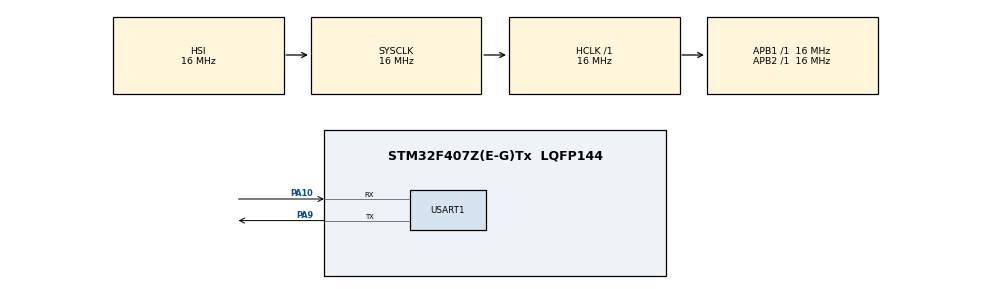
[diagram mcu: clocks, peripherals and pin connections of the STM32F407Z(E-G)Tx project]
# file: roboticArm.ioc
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Mcu.Family=STM32F4
Mcu.Name=STM32F407Z(E-G)Tx
Mcu.Package=LQFP144
NVIC.PriorityGroup=NVIC_PRIORITYGROUP_4
PA10.Mode=Asynchronous
PA10.Signal=USART1_RX
PA13.Mode=Serial_Wire
PA13.Signal=SYS_JTMS-SWDIO
PA14.Mode=Serial_Wire
PA14.Signal=SYS_JTCK-SWCLK
PA9.Mode=Asynchronous
PA9.Signal=USART1_TX
ProjectManager.HeapSize=0x200
ProjectManager.StackSize=0x400
ProjectManager.TargetToolchain=CMake
RCC.AHBFreq_Value=16000000
RCC.APB1Freq_Value=16000000
RCC.APB2Freq_Value=16000000
RCC.CortexFreq_Value=16000000
RCC.HSE_VALUE=25000000
RCC.HSI_VALUE=16000000
RCC.LSE_VALUE=32768
RCC.SYSCLKFreq_VALUE=16000000
RCC.VCOOutputFreq_Value=192000000
USART1.VirtualMode=VM_ASYNC
board=custom

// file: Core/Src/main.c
#include "main.h"
UART_HandleTypeDef huart1;

/* USER CODE BEGIN PV */
static const uint16_t servo_pulse_us[] = {1500U, 1300U, 1500U, 1700U};
static volatile uint32_t stepper_completed_moves = 0U;
/* USER CODE END PV */

void SystemClock_Config(void);
static void MX_GPIO_Init(void);
static void MX_USART1_UART_Init(void);

/* USER CODE BEGIN 0 */
/* D36A: STEP and DIR on GPIOC; active-high enables on GPIOD. */
#define STEP_A GPIO_PIN_6
#define DIR_A  GPIO_PIN_7
#define STEP_B GPIO_PIN_8
#define DIR_B  GPIO_PIN_9
#define EN_A   GPIO_PIN_6
#define EN_B   GPIO_PIN_7
static void Stepper_Init(void)
{
  __HAL_RCC_GPIOC_CLK_ENABLE();
  __HAL_RCC_GPIOD_CLK_ENABLE();

  /* Set the output latches before enabling the GPIO drivers. */
  HAL_GPIO_WritePin(GPIOD, EN_A | EN_B, GPIO_PIN_RESET);
  HAL_GPIO_WritePin(GPIOC, STEP_A | DIR_A | STEP_B | DIR_B, GPIO_PIN_RESET);

  GPIO_InitTypeDef pin = {0};
  pin.Mode = GPIO_MODE_OUTPUT_PP;
  pin.Pull = GPIO_NOPULL;
  pin.Speed = GPIO_SPEED_FREQ_LOW;
  pin.Pin = EN_A | EN_B;
  HAL_GPIO_Init(GPIOD, &pin);
  pin.Pin = STEP_A | DIR_A | STEP_B | DIR_B;
  HAL_GPIO_Init(GPIOC, &pin);
}

static void Stepper_Move(uint16_t step_pins, uint16_t dir_pins, GPIO_PinState direction)
{
  HAL_GPIO_WritePin(GPIOC, dir_pins, direction);
  HAL_Delay(5U);  /* Allow DIR to settle before the first rising edge. */

  for (uint32_t pulse = 0U; pulse < 200U; ++pulse)
  {
    HAL_GPIO_WritePin(GPIOC, step_pins, GPIO_PIN_SET);
    HAL_Delay(4U);
    HAL_GPIO_WritePin(GPIOC, step_pins, GPIO_PIN_RESET);
    HAL_Delay(4U);
  }

  ++stepper_completed_moves;
}
static void Stepper_RoundTrip(uint16_t step_pins, uint16_t dir_pins)
{
  Stepper_Move(step_pins, dir_pins, GPIO_PIN_SET);
  HAL_Delay(1000U);
  Stepper_Move(step_pins, dir_pins, GPIO_PIN_RESET);
  HAL_Delay(1000U);
}

static void Servo_PWM_Start(void)
{
  __HAL_RCC_GPIOA_CLK_ENABLE();
  __HAL_RCC_TIM3_CLK_ENABLE();

  uint32_t timer_hz = HAL_RCC_GetPCLK1Freq();
  if ((RCC->CFGR & RCC_CFGR_PPRE1) != 0U)
  {
    timer_hz *= 2U;
  }

  /* Count in microseconds. One PWM frame is 20 ms. */
  TIM3->PSC = timer_hz / 1000000U - 1U;
  TIM3->ARR = 20000U - 1U;
  TIM3->CCR1 = servo_pulse_us[0];
  TIM3->CCMR1 = TIM_CCMR1_OC1M_2 | TIM_CCMR1_OC1M_1 | TIM_CCMR1_OC1PE;
  TIM3->CR1 = TIM_CR1_ARPE;
  TIM3->EGR = TIM_EGR_UG;
  TIM3->SR = 0U;

  GPIO_InitTypeDef pin = {0};
  pin.Pin = GPIO_PIN_6;
  pin.Mode = GPIO_MODE_AF_PP;
  pin.Pull = GPIO_NOPULL;
  pin.Speed = GPIO_SPEED_FREQ_LOW;
  pin.Alternate = GPIO_AF2_TIM3;
  HAL_GPIO_Init(GPIOA, &pin);

  TIM3->CCER = TIM_CCER_CC1E;
  HAL_NVIC_SetPriority(TIM3_IRQn, 2U, 0U);
  HAL_NVIC_EnableIRQ(TIM3_IRQn);
  TIM3->DIER = TIM_DIER_UIE;
  TIM3->CR1 |= TIM_CR1_CEN;
}

/* TIM3 generates one update per 20 ms frame, even during stepper delays. */
void TIM3_IRQHandler(void)
{
  static uint32_t frames = 0U;
  static uint32_t position = 0U;

  TIM3->SR = ~TIM_SR_UIF;
  if (++frames == 50U)
  {
    frames = 0U;
    position = (position + 1U) % (sizeof(servo_pulse_us) / sizeof(servo_pulse_us[0]));
    TIM3->CCR1 = servo_pulse_us[position];
  }
}
/* USER CODE END 0 */

int main(void)
{

  /* MCU Configuration--------------------------------------------------------*/

  /* Reset of all peripherals, Initializes the Flash interface and the Systick. */
  HAL_Init();

  /* Configure the system clock */
  SystemClock_Config();

  /* Initialize all configured peripherals */
  MX_GPIO_Init();
  MX_USART1_UART_Init();
  /* USER CODE BEGIN 2 */
  Stepper_Init();
  Servo_PWM_Start();
  HAL_Delay(1000U);
  HAL_GPIO_WritePin(GPIOD, EN_A | EN_B, GPIO_PIN_SET);
  HAL_Delay(10U);  /* Allow the driver to wake up. */
  /* USER CODE END 2 */

  /* Infinite loop */
  while (1)
  {

    /* USER CODE BEGIN 3 */
    Stepper_RoundTrip(STEP_A, DIR_A);
    Stepper_RoundTrip(STEP_B, DIR_B);
    Stepper_RoundTrip(STEP_A | STEP_B, DIR_A | DIR_B);
  }
  /* USER CODE END 3 */
}

void SystemClock_Config(void)
{
  RCC_OscInitTypeDef RCC_OscInitStruct = {0};
  RCC_ClkInitTypeDef RCC_ClkInitStruct = {0};

  /** Configure the main internal regulator output voltage
  */
  __HAL_RCC_PWR_CLK_ENABLE();
  __HAL_PWR_VOLTAGESCALING_CONFIG(PWR_REGULATOR_VOLTAGE_SCALE1);

  /** Initializes the RCC Oscillators according to the specified parameters
  * in the RCC_OscInitTypeDef structure.
  */
  RCC_OscInitStruct.OscillatorType = RCC_OSCILLATORTYPE_HSI;
  RCC_OscInitStruct.HSIState = RCC_HSI_ON;
  RCC_OscInitStruct.HSICalibrationValue = RCC_HSICALIBRATION_DEFAULT;
  RCC_OscInitStruct.PLL.PLLState = RCC_PLL_NONE;
  if (HAL_RCC_OscConfig(&RCC_OscInitStruct) != HAL_OK)
  {
    Error_Handler();
  }

  /** Initializes the CPU, AHB and APB buses clocks
  */
  RCC_ClkInitStruct.ClockType = RCC_CLOCKTYPE_HCLK|RCC_CLOCKTYPE_SYSCLK
                              |RCC_CLOCKTYPE_PCLK1|RCC_CLOCKTYPE_PCLK2;
  RCC_ClkInitStruct.SYSCLKSource = RCC_SYSCLKSOURCE_HSI;
  RCC_ClkInitStruct.AHBCLKDivider = RCC_SYSCLK_DIV1;
  RCC_ClkInitStruct.APB1CLKDivider = RCC_HCLK_DIV1;
  RCC_ClkInitStruct.APB2CLKDivider = RCC_HCLK_DIV1;

  if (HAL_RCC_ClockConfig(&RCC_ClkInitStruct, FLASH_LATENCY_0) != HAL_OK)
  {
    Error_Handler();
  }
}

static void MX_USART1_UART_Init(void)
{

  huart1.Instance = USART1;
  huart1.Init.BaudRate = 115200;
  huart1.Init.WordLength = UART_WORDLENGTH_8B;
  huart1.Init.StopBits = UART_STOPBITS_1;
  huart1.Init.Parity = UART_PARITY_NONE;
  huart1.Init.Mode = UART_MODE_TX_RX;
  huart1.Init.HwFlowCtl = UART_HWCONTROL_NONE;
  huart1.Init.OverSampling = UART_OVERSAMPLING_16;
  if (HAL_UART_Init(&huart1) != HAL_OK)
  {
    Error_Handler();
  }

}

static void MX_GPIO_Init(void)
{

  /* GPIO Ports Clock Enable */
  __HAL_RCC_GPIOA_CLK_ENABLE();

}

void Error_Handler(void)
{
  __disable_irq();
  while (1)
  {
  }
}
